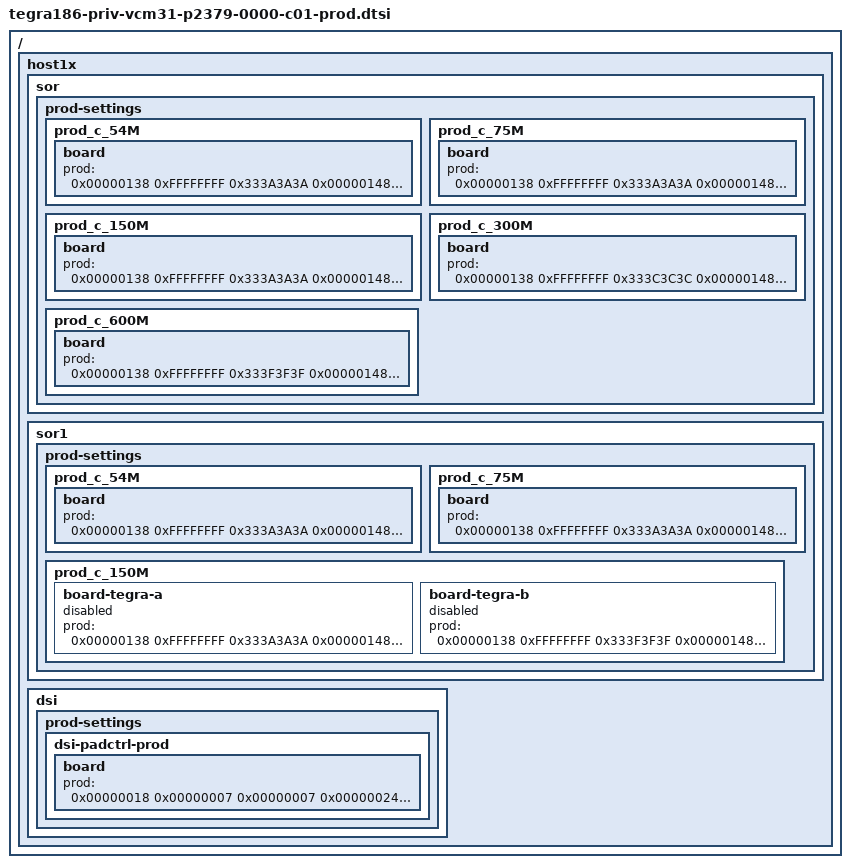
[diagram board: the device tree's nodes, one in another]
/*
 * P2379 Tegras A and B (Drive PX2) specific Prod configuration.
 *
 * Copyright (c) 2016, NVIDIA CORPORATION.  All rights reserved.
 *
 * This program is free software; you can redistribute it and/or modify
 * it under the terms of the GNU General Public License as published by
 * the Free Software Foundation; version 2 of the License.
 *
 */

/ {
	host1x {
		sor{
			prod-settings {
				prod_c_54M {
					board {
						prod = <
							0x00000138 0xFFFFFFFF 0x333A3A3A
							0x00000148 0xFFFFFFFF 0x00000000
							0x0000058C 0x0F0F0F00 0x05050000
							0x00000590 0x00F01F00 0x00301300
							0x00000598 0xFF000FF0 0x38000440
							0x000005A0 0x0040FF00 0x00401000
							0x000005A8 0xFF000000 0x52000000
						>;
					};
				};

				prod_c_75M {
					board {
						prod = <
							0x00000138 0xFFFFFFFF 0x333A3A3A
							0x00000148 0xFFFFFFFF 0x00000000
							0x0000058C 0x0F0F0F00 0x05050100
							0x00000590 0x00F01F00 0x00301300
							0x00000598 0xFF000FF0 0x38000440
							0x000005A0 0x0040FF00 0x00404000
							0x000005A8 0xFF000000 0x42000000
						>;
					};
				};

				prod_c_150M {
					board {
						prod = <
							0x00000138 0xFFFFFFFF 0x333A3A3A
							0x00000148 0xFFFFFFFF 0x00000000
							0x0000058C 0x0F0F0F00 0x05050300
							0x00000590 0x00F01F00 0x00301300
							0x00000598 0xFF000FF0 0x38000440
							0x000005A0 0x0040FF00 0x00406600
							0x000005A8 0xFF000000 0x32000000
						>;
					};
				};

				prod_c_300M {
					board {
						prod = <
							0x00000138 0xFFFFFFFF 0x333C3C3C
							0x00000148 0xFFFFFFFF 0x001F1F1F
							0x0000058C 0x0F0F0F00 0x05050300
							0x00000590 0x00F01F00 0x00301300
							0x00000598 0xFF000FF0 0x3C000440
							0x000005A0 0x0040FF00 0x00406600
							0x000005A8 0xFF000000 0x32000000
						>;
					};
				};

				prod_c_600M {
					board {
						prod = <
							0x00000138 0xFFFFFFFF 0x333F3F3F
							0x00000148 0xFFFFFFFF 0x001F1F1F
							0x0000058C 0x0F0F0F00 0x05050300
							0x00000590 0x00F01F00 0x00301300
							0x00000598 0xFF000FF0 0x3C000440
							0x000005A0 0x0040FF00 0x00406600
							0x000005A8 0xFF000000 0x32000000
						>;
					};
				};
			};
		};

		sor1 {
			prod-settings {
				prod_c_54M {
					board {
						prod = <
							0x00000138 0xFFFFFFFF 0x333A3A3A
							0x00000148 0xFFFFFFFF 0x00000000
							0x0000058C 0x0F0F0F00 0x05050000
							0x00000590 0x00F01F00 0x00301300
							0x00000598 0xFF000FF0 0x38000440
							0x000005A0 0x0040FF00 0x00401000
							0x000005A8 0xFF000000 0x52000000
						>;
					};
				};

				prod_c_75M {
					board {
						prod = <
							0x00000138 0xFFFFFFFF 0x333A3A3A
							0x00000148 0xFFFFFFFF 0x00000000
							0x0000058C 0x0F0F0F00 0x05050100
							0x00000590 0x00F01F00 0x00301300
							0x00000598 0xFF000FF0 0x38000440
							0x000005A0 0x0040FF00 0x00404000
							0x000005A8 0xFF000000 0x42000000
						>;
					};
				};

				prod_c_150M {
					board-tegra-a {
						status = "disabled";

						prod = <
							0x00000138 0xFFFFFFFF 0x333A3A3A
							0x00000148 0xFFFFFFFF 0x00000000
							0x0000058C 0x0F0F0F00 0x05050300
							0x00000590 0x00F01F00 0x00301300
							0x00000598 0xFF000FF0 0x38000440
							0x000005A0 0x0040FF00 0x00406600
							0x000005A8 0xFF000000 0x32000000
						>;
					};


					board-tegra-b {
						status = "disabled";

						prod = <
							0x00000138 0xFFFFFFFF 0x333F3F3F
							0x00000148 0xFFFFFFFF 0x001F1F1F
							0x0000058C 0x0F0F0F00 0x05050300
							0x00000590 0x00F01F00 0x00301300
							0x00000598 0xFF000FF0 0x38000440
							0x000005A0 0x0040FF00 0x00406600
							0x000005A8 0xFF000000 0x32000000
						>;
					};
				};
			};
		};

		dsi {
			prod-settings {
				dsi-padctrl-prod {
					board {
						prod = <
							0x00000018 0x00000007 0x00000007
							0x00000024 0x03F0FC3F 0x00000000
							0x00000028 0x00333333 0x00333333
							0x00000030 0x00FFFFFF 0x00000000
							0x00000034 0x00FFFFFF 0x00777777
							0x00000048 0x00000006 0x00000006
							0x00000054 0x03F0FC3F 0x00000000
							0x00000058 0x00330330 0x00330330
							0x00000060 0x00FF0FF0 0x00000000
							0x00000064 0x00FF0FF0 0x00770770
						>;
					};
				};
			};
		};
	};
};
